# NM1330AE_v1 register map
File version: 1.0
Registers are 32-bit, read-write, reset 0x0 unless marked. A register's access mark holds for its fields unless they carry their own. Offsets are from the block's base; [hi:lo] are bit positions; {n}, {i} and the like mark numbered series; 'fields as' and 'values as' point back to an identical list.

## EBI — EBI Register Map
Base 0x50010000
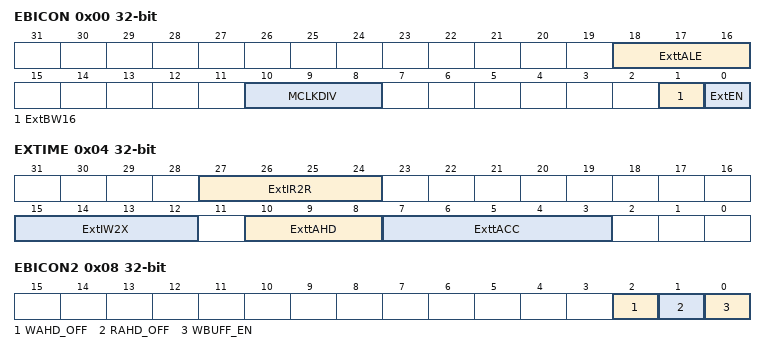
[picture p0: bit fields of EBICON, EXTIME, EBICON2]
0x00 EBICON — External Bus Interface General Control Register
  [18:16] ExttALE — Expand Time of ALE. This field is used to control the ALE pulse width (tALE) for address latch.
  [10:8] MCLKDIV — External Output Clock Divider. The frequency of EBI output clock (MCLK) is controlled by MCLKDIV as follows: Note: The default value of output clock is HCLK/1.
    0=MCLK frequency is HCLK/1; 1=MCLK frequency is HCLK/2; 2=MCLK frequency is HCLK/4; 3=MCLK frequency is HCLK/8; 4=MCLK frequency is HCLK/16; 5=MCLK frequency is HCLK/32
  [1] ExtBW16 — EBI Data Width 16-bit / 8-bit. This bit defines if the data bus is 8-bit or 16-bit.
    0=EBI data width is 8 bit; 1=EBI data width is 16 bit
  [0] ExtEN — EBI Enable Control. This bit is the functional enable bit for EBI.
    0=EBI function Disabled; 1=EBI function Enabled
0x04 EXTIME — External Bus Interface Timing Control Register
  [27:24] ExtIR2R — Idle State Cycle Between Read-Read. When read action is finished and the next action is going to read, idle state is inserted and nCS signal return to high if ExtIR2R is not 0.
  [15:12] ExtIW2X — Idle State Cycle After Write. When write action is finished, idle state is inserted and nCS signal return to high if ExtIW2X is not 0.
  [10:8] ExttAHD — EBI Data Access Hold Time. ExttAHD defines data access hold time (tAHD).
  [7:3] ExttACC — EBI Data Access Time. ExttACC defines data access time (tACC).
0x08 EBICON2 — External Bus Interface General Control Register 2
  [2] WAHD_OFF — Access Hold Time Disable Control When Write
    0=tAHD is controlled by ExttAHD[2:0] when write through EBI; 1=Zero tAHD when write through EBI
  [1] RAHD_OFF — Access Hold Time Disable Control When Read
    0=tAHD is controlled by ExttAHD[2:0] when read through EBI; 1=Zero tAHD when read through EBI
  [0] WBUFF_EN — EBI Write Buffer Enable Control. Enable this function to improve CPU and EBI access performance.
    0=EBI write buffer Disabled; 1=EBI write buffer Enabled

## HDIV — HDIV Register Map
Base 0x50014000
0x00 DIVIDEND — Dividend Source Register
  [31:0] DIVIDEND — Dividend Source. This register is given the dividend of divider before calculation starting.
0x04 DIVISOR reset 0xFFFF — Divisor Source Resister
  [15:0] DIVISOR — Divisor Source. This register is given the divisor of divider before calculation starts. Note: When this register is written, hardware divider will start calculate.
0x08 DIVQUO — Quotient Result Resister
  [31:0] QUOTIENT — Quotient Result. This register holds the quotient result of divider after calculation complete.
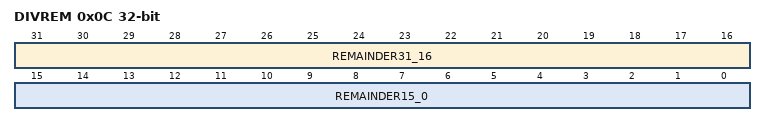
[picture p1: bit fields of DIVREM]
0x0C DIVREM — Remainder Result Register
  [31:16] REMAINDER31_16 — Sign Extension of REMAINDER[15:0]. The remainder of hardware divider is 16-bit sign integer (REMAINDER[15:0]) with sign extension (REMAINDER[31:16]) to 32-bit integer.
  [15:0] REMAINDER15_0 — Remainder Result. This register holds the remainder result of divider after calculation complete.
0x10 DIVSTS ro reset 0x1 — Divider Status Register
  [1] DIV0 — Divisor Zero Warning. Note: The DIV0 flag is used to indicate divide-by-zero situation and updated whenever DIVISOR is written. This register is read only.
    0=The divisor is not 0; 1=The divisor is 0

## I2C0 — I2C Register Map
Base 0x40020000
Same registers: I2C1 0x40120000
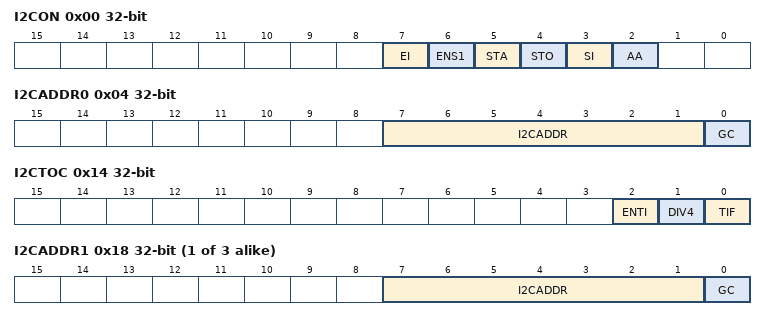
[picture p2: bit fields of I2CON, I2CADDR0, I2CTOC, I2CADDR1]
0x00 I2CON — I2C Control Register
  [7] EI — I2C Interrupt Enable Control
    0=I2C interrupt Disabled; 1=I2C interrupt Enabled
  [6] ENS1 — I2C Controller Enable Control
    0=I2C Controller Disabled; 1=I2C Controller Enabled
  [5] STA — I2C START Control. Setting STA to logic 1 to enter Master mode, the I2C hardware sends a START or repeat START condition to bus when the bus is free.
  [4] STO — I2C STOP Control. In master mode, setting STO to transmit a STOP condition to bus then I2C hardware will check the bus condition if a STOP condition is detected this bit will be cleared by hardware automatically. In Slave mode, setting STO resets I2C hardware to the defined "not addressed" Slave mode. This means it is NO LONGER in the slave receiver mode to receive data from the master transmit device.
  [3] SI — I2C Interrupt Flag. When a new I2C state is present in the I2CSTATUS register, the SI flag is set by hardware, and if bit EI (I2CON [7]) is set, the I2C interrupt is requested. SI must be cleared by software. Clear SI is by writing 1 to it.
  [2] AA — Assert Acknowledge Control
0x04 I2CADDR0 — I2C Slave Address Register0
  [7:1] I2CADDR — I2C Address Register. The content of this register is irrelevant when I2C is in Master mode. In Slave mode, the seven most significant bits must be loaded with the chip's own address. The I2C hardware will react if one of the addresses is matched.
  [0] GC — General Call Function Enable Control
    0=General Call function Disabled; 1=General Call Function Enabled
0x08 I2CDAT — I2C Data Register
  [7:0] I2CDAT — I2C Data Register. Bit [7:0] is located with the 8-bit transferred data of I2C serial port.
0x0C I2CSTATUS ro reset 0xF8
  [7:0] I2CSTATUS
0x10 I2CLK — I2C Clock Divided Register
  [7:0] I2CLK — I2C Clock Divided. Note: The minimum value of I2CLK is 4.
0x14 I2CTOC — I2C Time-out Counter Register
  [2] ENTI — Time-out Counter Enable Control. Note: When the 14 bit Time-out counter is enabled, it will start counting when SI is cleared. Writing 1 to the Si flag will reset the counter and re-start up counting after SI is cleared.
    0=Time-out counter Disabled; 1=Time-out counter Enabled
  [1] DIV4 — Time-out Counter Input Clock Divided by 4. Note: When Enabled, the time-out period is extended 4 times.
    0=Time-out counter input clock divided by 4 Disabled; 1=Time-out counter input clock divided by 4 Enabled
  [0] TIF — Time-out Flag. This bit is set by hardware when I2C time-out happened and it can interrupt CPU if I2C interrupt enable bit (EI) is set to 1. Note: Software can write 1 to clear this bit.
{0x14+4i} I2CADDR{i} (i=1..3) — I2C Slave Address Register0
  fields as I2CADDR0
{0x24+4i} I2CADM{i} (i=0..3) — I2C Slave Address Mask Register0
  [7:1] I2CADM — I2C Address Mask
    0=I2C address mask Disabled (the received corresponding register bit should be exactly the same as address register); 1=I2C address mask Enabled (the received corresponding address bit is "Don't care")
0x3C I2CWKUPCON — I2C Wake-up Control Register
  [0] WKUPEN — I2C Wakeup Function Enable Control
    0=I2C wake up function Disabled; 1=I2C wake up function Enabled
0x40 I2CWKUPSTS — I2C Wake-up Status Register
  [0] WKUPIF — I2C Wake-up Interrupt Flag. When chip is woken up from Power-Down mode by I2C, this bit is set to 1. Software can write 1 to clear this bit.
